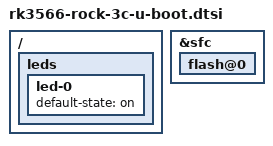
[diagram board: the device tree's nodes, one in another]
// SPDX-License-Identifier: (GPL-2.0+ OR MIT)

#include "rk356x-u-boot.dtsi"

/ {
	leds {
		led-0 {
			default-state = "on";
		};
	};
};

&sfc {
	flash@0 {
		bootph-pre-ram;
		bootph-some-ram;
	};
};
